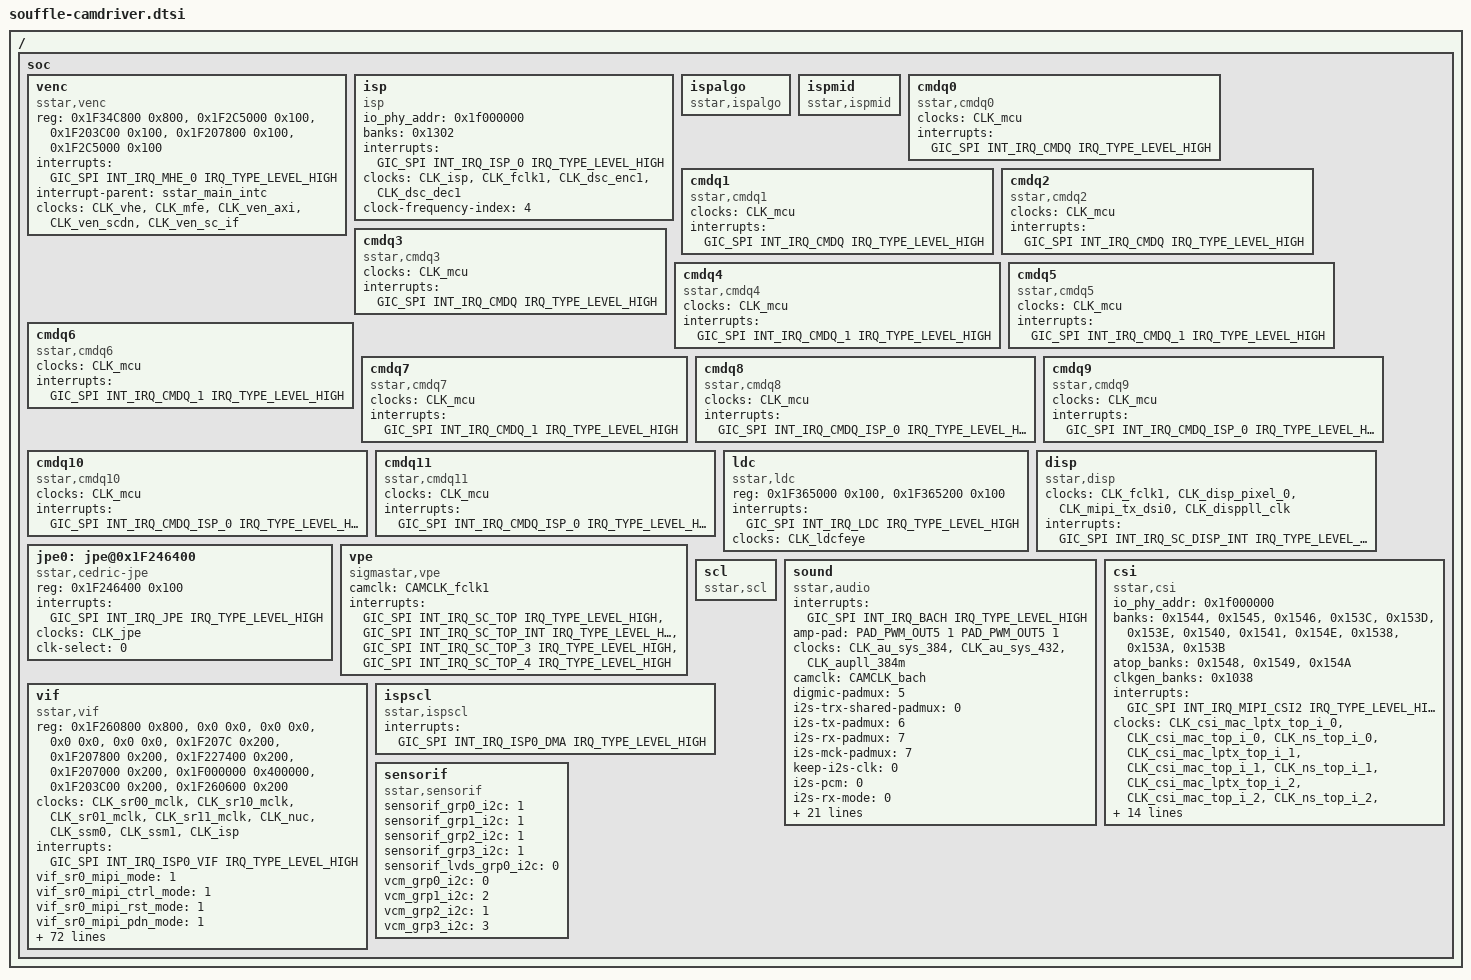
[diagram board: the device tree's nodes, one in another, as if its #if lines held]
/*
* souffle-camdriver.dtsi- Sigmastar
*
* Copyright (c) [2019~2020] SigmaStar Technology.
*
*
* This software is licensed under the terms of the GNU General Public
* License version 2, as published by the Free Software Foundation, and
* may be copied, distributed, and modified under those terms.
*
* This program is distributed in the hope that it will be useful,
* but WITHOUT ANY WARRANTY; without even the implied warranty of
* MERCHANTABILITY or FITNESS FOR A PARTICULAR PURPOSE.  See the
* GNU General Public License version 2 for more details.
*
*/
#include "../../../../include/generated/autoconf.h"
#include "../../../../drivers/sstar/include/souffle/irqs.h"
#include "../../../../drivers/sstar/include/souffle/gpio.h"
#include <dt-bindings/interrupt-controller/irq.h>
#include <dt-bindings/interrupt-controller/arm-gic.h>
#include <dt-bindings/input/input.h>


/ {
    soc {
        venc {
            compatible = "sstar,venc";
            reg = <0x1F34C800 0x800>, <0x1F2C5000 0x100>, <0x1F203C00 0x100>, <0x1F207800 0x100>, <0x1F2C5000 0x100>;
            reg-names = "vpu-bit", "venc-brige", "hw-uart0", "hw-uart1", "venc-gp";
            interrupts = <GIC_SPI INT_IRQ_MHE_0 IRQ_TYPE_LEVEL_HIGH>;
            interrupt-parent = <&sstar_main_intc>;
            interrupt-names = "mhe-irq";
            clocks = <&CLK_vhe>, <&CLK_mfe>, <&CLK_ven_axi>,<&CLK_ven_scdn>,<&CLK_ven_sc_if>;
            clock-names = "CKG_venc";
            status = "ok";
        };

        isp: isp {
            compatible = "isp";
            io_phy_addr = <0x1f000000>;
            banks = <0x1302>;
            interrupts = <GIC_SPI INT_IRQ_ISP_0 IRQ_TYPE_LEVEL_HIGH>;
            clocks = <&CLK_isp>,<&CLK_fclk1>,<&CLK_dsc_enc1>,<&CLK_dsc_dec1>;
            status = "ok";
            clock-frequency-index = <4>;
        };

        ispalgo: ispalgo {
            compatible = "sstar,ispalgo";
            status = "ok";
        };

/*
        ispscl: ispscl {
            compatible = "sstar,ispscl";
            interrupts = <GIC_SPI INT_IRQ_ISP0_DMA IRQ_TYPE_LEVEL_HIGH>;
            status = "ok";
        };
*/

        ispmid: ispmid {
            compatible = "sstar,ispmid";
            status = "ok";
        };

        cmdq0 {
            compatible = "sstar,cmdq0";
            clocks = <&CLK_mcu>; //for timeout tick
            interrupts=<GIC_SPI INT_IRQ_CMDQ IRQ_TYPE_LEVEL_HIGH>;
            status = "ok";
        };

        cmdq1 {
            compatible = "sstar,cmdq1";
            clocks = <&CLK_mcu>; //for timeout tick
            interrupts=<GIC_SPI INT_IRQ_CMDQ IRQ_TYPE_LEVEL_HIGH>;
            status = "ok";
        };

        cmdq2 {
            compatible = "sstar,cmdq2";
            clocks = <&CLK_mcu>; //for timeout tick
            interrupts=<GIC_SPI INT_IRQ_CMDQ IRQ_TYPE_LEVEL_HIGH>;
            status = "ok";
        };

        cmdq3 {
            compatible = "sstar,cmdq3";
            clocks = <&CLK_mcu>; //for timeout tick
            interrupts=<GIC_SPI INT_IRQ_CMDQ IRQ_TYPE_LEVEL_HIGH>;
            status = "ok";
        };

        cmdq4 {
            compatible = "sstar,cmdq4";
            clocks = <&CLK_mcu>; //for timeout tick
            interrupts=<GIC_SPI INT_IRQ_CMDQ_1 IRQ_TYPE_LEVEL_HIGH>;
            status = "ok";
        };

        cmdq5 {
            compatible = "sstar,cmdq5";
            clocks = <&CLK_mcu>; //for timeout tick
            interrupts=<GIC_SPI INT_IRQ_CMDQ_1 IRQ_TYPE_LEVEL_HIGH>;
            status = "ok";
        };

        cmdq6 {
            compatible = "sstar,cmdq6";
            clocks = <&CLK_mcu>; //for timeout tick
            interrupts=<GIC_SPI INT_IRQ_CMDQ_1 IRQ_TYPE_LEVEL_HIGH>;
            status = "ok";
        };
        cmdq7 {
            compatible = "sstar,cmdq7";
            clocks = <&CLK_mcu>; //for timeout tick
            interrupts=<GIC_SPI INT_IRQ_CMDQ_1 IRQ_TYPE_LEVEL_HIGH>;
            status = "ok";
        };

        cmdq8 {
            compatible = "sstar,cmdq8";
            clocks = <&CLK_mcu>; //for timeout tick
            interrupts=<GIC_SPI INT_IRQ_CMDQ_ISP_0 IRQ_TYPE_LEVEL_HIGH>;
            status = "ok";
        };

        cmdq9 {
            compatible = "sstar,cmdq9";
            clocks = <&CLK_mcu>; //for timeout tick
            interrupts=<GIC_SPI INT_IRQ_CMDQ_ISP_0 IRQ_TYPE_LEVEL_HIGH>;
            status = "ok";
        };

        cmdq10 {
            compatible = "sstar,cmdq10";
            clocks = <&CLK_mcu>; //for timeout tick
            interrupts=<GIC_SPI INT_IRQ_CMDQ_ISP_0 IRQ_TYPE_LEVEL_HIGH>;
            status = "ok";
        };

        cmdq11 {
            compatible = "sstar,cmdq11";
            clocks = <&CLK_mcu>; //for timeout tick
            interrupts=<GIC_SPI INT_IRQ_CMDQ_ISP_0 IRQ_TYPE_LEVEL_HIGH>;
            status = "ok";
        };

        ldc: ldc {
            compatible = "sstar,ldc";
            reg = <0x1F365000 0x100>, <0x1F365200 0x100>;
            interrupts=<GIC_SPI INT_IRQ_LDC IRQ_TYPE_LEVEL_HIGH>;
            clocks = <&CLK_ldcfeye>;
            status = "ok";
        };

        disp: disp {
            compatible = "sstar,disp";
            status = "ok";
            clocks = <&CLK_fclk1>, <&CLK_disp_pixel_0>, <&CLK_mipi_tx_dsi0>, <&CLK_disppll_clk>;
            interrupts = <GIC_SPI INT_IRQ_SC_DISP_INT IRQ_TYPE_LEVEL_HIGH>;
            //Reg = <0x1F224000 0x200>;
        };

        jpe0: jpe@0x1F246400 {
            compatible = "sstar,cedric-jpe";
            reg = <0x1F246400 0x100>;
            interrupts = <GIC_SPI INT_IRQ_JPE IRQ_TYPE_LEVEL_HIGH>;
            clocks = <&CLK_jpe>;
            clock-names = "CKG_jpe";
            interrupt-names = "jpe-irq0";
            clk-select = <0>; // 0: 480M  1: 432MHz  2: 384MHz  3: 320MHz 4: 288MHz 5:216MHz
            status = "ok";
        };

        vpe: vpe {
            compatible = "sigmastar,vpe";
            status = "ok";
            #ifdef CONFIG_CAM_CLK
            camclk = <CAMCLK_fclk1>;
            #else
            clocks = <&CLK_fclk1>,<&CLK_ven_sc_if>;
            #endif
            interrupts = <GIC_SPI INT_IRQ_SC_TOP IRQ_TYPE_LEVEL_HIGH>, <GIC_SPI INT_IRQ_SC_TOP_INT IRQ_TYPE_LEVEL_HIGH>, <GIC_SPI INT_IRQ_SC_TOP_3 IRQ_TYPE_LEVEL_HIGH>, <GIC_SPI INT_IRQ_SC_TOP_4 IRQ_TYPE_LEVEL_HIGH>;
        };

        scl: scl {
            compatible = "sstar,scl";
            status = "ok";
        };

        sound {
            compatible = "sstar,audio";
            interrupts=<GIC_SPI INT_IRQ_BACH IRQ_TYPE_LEVEL_HIGH>;
            amp-pad = <PAD_PWM_OUT5 1 PAD_PWM_OUT5 1>;
            clocks = <&CLK_au_sys_384>, <&CLK_au_sys_432>, <&CLK_aupll_384m>;
#ifdef CONFIG_CAM_CLK
            camclk = <CAMCLK_bach>;
#endif
            // padmux
            digmic-padmux = <5>;
            i2s-trx-shared-padmux = <0>; //for 4-wired mode panmux
            i2s-tx-padmux = <6>; //6-wired mode
            i2s-rx-padmux = <7>; //6-wired mode
            i2s-mck-padmux = <7>;

            keep-i2s-clk = <0>;
            i2s-pcm = <0>;
            i2s-rx-mode = <0>;

            // I2S RX TDM
            i2s-rx0-tdm-ws-pgm = <0>;   // 0: OFF  1: ON
            i2s-rx0-tdm-ws-width = <0>; // value: 0~31 (width = value + 1)
            i2s-rx0-tdm-ws-inv = <0>;   // 0: normal  1: inverse WCK
            i2s-rx0-tdm-bck-inv = <0>;  // 0: normal  1: inverse BCK
            i2s-rx0-tdm-ch-swap = <0 0 0 0>; // 0: OFF  1: ON

            // I2S TX TDM
            i2s-tx0-tdm-ws-pgm = <0>;   // 0: OFF  1: ON
            i2s-tx0-tdm-ws-width = <0>; // value: 0~31 (width = value + 1)
            i2s-tx0-tdm-ws-inv = <0>;   // 0: normal  1: inverse WCK
            i2s-tx0-tdm-bck-inv = <0>;  // 0: normal  1: inverse BCK
            i2s-tx0-tdm-ch-swap = <0 0 0 0>; // 0: OFF  1: ON
            i2s-tx0-tdm-active-slot = <0xFFFF>; // value: 0x00 ~ 0xFF (bit0->slot0, bit1->slot1, ... )

            // dmic bck mode
            dmic-bck-mode = <3 6 9 11>;    //2.4M, 2.4M, 4.8M, 4.8M
            dmic-bck-ext-mode = <0>;

            // hpf default level
            hpf-adc1-dmic2ch-level = <1 0x3>;//1:Enable HPF  0:Disable HPF; 0x3:hpf level is 3;
            hpf-adc2-level         = <1 0x3>;//Enable HPF, hpf level is 0x03;hpf level support: 0x00~0x0F
            hpf-dmic4ch-level      = <0 0x0>;//Bypass HPF; the smaller hpf level value,the stronger the filtering capability

            keep_adc_power_on = <0>;
            keep_dac_power_on = <0>;

            i2s-rx-short-ff-mode = <0>;
            i2s-tx-short-ff-mode = <0>;

            adc-out-sel = <0 1 2 2>;

            status = "ok";
        };

        csi: csi {
            compatible = "sstar,csi";
            io_phy_addr = <0x1f000000>;
            banks = <0x1544>,<0x1545>,<0x1546>,<0x153C>,<0x153D>,<0x153E>,<0x1540>,<0x1541>,<0x154E>,<0x1538>,<0x153A>,<0x153B>;
            atop_banks = <0x1548>,<0x1549>,<0x154A>;
            clkgen_banks = <0x1038>;
            interrupts=  <GIC_SPI INT_IRQ_MIPI_CSI2 IRQ_TYPE_LEVEL_HIGH>;
            clocks = <&CLK_csi_mac_lptx_top_i_0>,<&CLK_csi_mac_top_i_0>,<&CLK_ns_top_i_0>,<&CLK_csi_mac_lptx_top_i_1>,<&CLK_csi_mac_top_i_1>,<&CLK_ns_top_i_1>,<&CLK_csi_mac_lptx_top_i_2>,<&CLK_csi_mac_top_i_2>,<&CLK_ns_top_i_2>,<&CLK_csi_mac_lptx_top_i_3>,<&CLK_csi_mac_top_i_3>,<&CLK_ns_top_i_3>;
            //clocks = <&CLK_csi_mac_lptx_top_i_m00>,<&CLK_csi_mac_top_i_m00>,<&CLK_ns_top_i_m00>,<&CLK_csi_mac_lptx_top_i_m01>,<&CLK_csi_mac_top_i_m01>,<&CLK_ns_top_i_m01>;
            status = "ok";
            /* Config max lane number */
            csi_sr0_lane_num = <4>;
            csi_sr1_lane_num = <4>;
            csi_sr2_lane_num = <2>;
            csi_sr3_lane_num = <2>;
            /* Config lane selection */
            csi_sr0_lane_select = <2 1 3 0 4>;
            csi_sr1_lane_select = <2 1 3 0 4>;
            csi_sr2_lane_select = <2 1 0>;
            csi_sr3_lane_select = <2 1 0>;
            /* Config lane P/N swap */
            csi_sr0_lane_pn_swap = <0 0 0 0 0>;
            csi_sr1_lane_pn_swap = <0 0 0 0 0>;
            csi_sr2_lane_pn_swap = <0 0 0>;
            csi_sr3_lane_pn_swap = <0 0 0>;
        };

        vif: vif {
            compatible = "sstar,vif";
            status = "ok";
            reg = <0x1F260800 0x800>, <0x0 0x0>, <0x0 0x0>, <0x0 0x0>, <0x0 0x0>, <0x1F207C 0x200>, <0x1F207800 0x200>, <0x1F227400 0x200>, <0x1F207000 0x200>, <0x1F000000 0x400000>, <0x1F203C00 0x200>, <0x1F260600 0x200>;
            clocks = <&CLK_sr00_mclk>,<&CLK_sr10_mclk>,<&CLK_sr01_mclk>,<&CLK_sr11_mclk>,<&CLK_nuc>,<&CLK_ssm0>,<&CLK_ssm1>,<&CLK_isp>;
            interrupts = <GIC_SPI INT_IRQ_ISP0_VIF IRQ_TYPE_LEVEL_HIGH>;
            /* Config sensor 0 pad mux */
            vif_sr0_mipi_mode         = <1>;
            vif_sr0_mipi_ctrl_mode    = <1>;
            vif_sr0_mipi_rst_mode     = <1>;
            vif_sr0_mipi_pdn_mode     = <1>;
            vif_sr0_mipi_mclk_mode    = <1>;
            vif_sr0_mipi_mclk_id      = <0>;
            vif_sr0_par_mode          = <1>;
            vif_sr0_par_ctrl_mode     = <1>;
            vif_sr0_par_rst_mode      = <1>;
            vif_sr0_par_pdn_mode      = <1>;
            vif_sr0_par_mclk_mode     = <1>;
            vif_sr0_par_sync_mode     = <1>;
            vif_sr0_par_pclk_mode     = <1>;
            vif_sr0_par_mclk_id       = <0>;
            vif_sr0_bt656_mode        = <1>;
            vif_sr0_bt656_ctrl_mode   = <1>;
            vif_sr0_bt656_rst_mode    = <1>;
            vif_sr0_bt656_pdn_mode    = <1>;
            vif_sr0_bt656_mclk_mode   = <1>;
            vif_sr0_bt656_mclk_id     = <0>;
            vif_sr0_bt1120_mode       = <1>;
            vif_sr0_bt1120_ctrl_mode  = <1>;
            vif_sr0_bt1120_rst_mode   = <1>;
            vif_sr0_bt1120_pdn_mode   = <1>;
            vif_sr0_bt1120_mclk_mode  = <1>;
            vif_sr0_bt1120_mclk_id    = <0>;
            vif_sr0_lvds_mode         = <1>;
            vif_sr0_lvds_ctrl_mode    = <1>;
            vif_sr0_lvds_rst_mode     = <1>;
            vif_sr0_lvds_pdn_mode     = <1>;
            vif_sr0_lvds_mclk_mode    = <1>;
            vif_sr0_lvds_mclk_id      = <0>;
            vif_sr0_lvds_rst_id       = <0>;
            vif_sr0_ir_infrared_mode  = <2>;
            vif_sr0_ir_sr0_mode       = <5>;
            vif_sr0_ir_pclk_mode      = <4>;
            vif_sr0_ir_hsync_mode     = <1>;
            vif_sr0_ir_vsync_mode     = <1>;
            vif_sr0_ir_used_i2c_pad   = <1>;  /* Attention: Infrared sensor interface will use PAD_I2C1_SCL and PAD_I2C1_SDA */
            vif_sr0_ir_rst_mode       = <1>;
            vif_sr0_ir_mclk_mode      = <1>;
            vif_sr0_ir_vdet_on_pad_index = <59>;
            vif_sr0_ir_avdd_on_pad_index = <60>;

            /* Config sensor 2 pad mux */
            vif_sr1_mipi_mode         = <1>;
            vif_sr1_mipi_ctrl_mode    = <1>;
            vif_sr1_mipi_rst_mode     = <1>;
            vif_sr1_mipi_pdn_mode     = <1>;
            vif_sr1_mipi_mclk_mode    = <1>;
            vif_sr1_mipi_mclk_id      = <1>;
            vif_sr1_par_mode          = <1>;
            vif_sr1_par_rst_mode      = <1>;
            vif_sr1_par_ctrl_mode     = <1>;
            vif_sr1_par_pdn_mode      = <1>;
            vif_sr1_par_mclk_mode     = <1>;
            vif_sr1_par_mclk_id       = <1>;
            vif_sr1_bt656_mode        = <1>;
            vif_sr1_bt656_ctrl_mode   = <1>;
            vif_sr1_bt656_rst_mode    = <1>;
            vif_sr1_bt656_pdn_mode    = <1>;
            vif_sr1_bt656_mclk_mode   = <1>;
            vif_sr1_bt656_mclk_id     = <1>;

            /* Config sensor 1 pad mux */
            vif_sr2_mipi_mode         = <1>;
            vif_sr2_mipi_ctrl_mode    = <1>;
            vif_sr2_mipi_rst_mode     = <1>;
            vif_sr2_mipi_pdn_mode     = <1>;
            vif_sr2_mipi_mclk_mode    = <1>;
            vif_sr2_mipi_mclk_id      = <2>;

            /* Config sensor 3 pad mux */
            vif_sr3_mipi_mode         = <1>;
            vif_sr3_mipi_ctrl_mode    = <2>;
            vif_sr3_mipi_rst_mode     = <1>;
            vif_sr3_mipi_pdn_mode     = <1>;
            vif_sr3_mipi_mclk_mode    = <1>;
            vif_sr3_mipi_mclk_id      = <3>;

            /* Config mclk 37.125MHz supported */
            vif_sr0_mclk_37p125 = <1>;
            vif_sr1_mclk_37p125 = <1>;
            vif_sr2_mclk_37p125 = <1>;
        };

        ispscl: ispscl {
            compatible = "sstar,ispscl";
            interrupts = <GIC_SPI INT_IRQ_ISP0_DMA IRQ_TYPE_LEVEL_HIGH>;
            status = "ok";
        };

        sensorif: sensorif {
            compatible = "sstar,sensorif";
            status = "ok";
            sensorif_grp0_i2c = <1>;
            sensorif_grp1_i2c = <1>;
            sensorif_grp2_i2c = <1>;
            sensorif_grp3_i2c = <1>;
            sensorif_lvds_grp0_i2c = <0>;

            /* vcm i2c bus select*/
            vcm_grp0_i2c = <0>;
            vcm_grp1_i2c = <2>;
            vcm_grp2_i2c = <1>;
            vcm_grp3_i2c = <3>;
        };

    };
};
